# RL7005_IP_SVD register map
Vendor: Realtek
Registers are 32-bit, read-write, reset 0x0 unless marked. A register's access mark holds for its fields unless they carry their own. Offsets are from the block's base; [hi:lo] are bit positions; lines under a group give offsets from that group; {n}, {i} and the like mark numbered series.

## PAGE4
Base 0x40000000
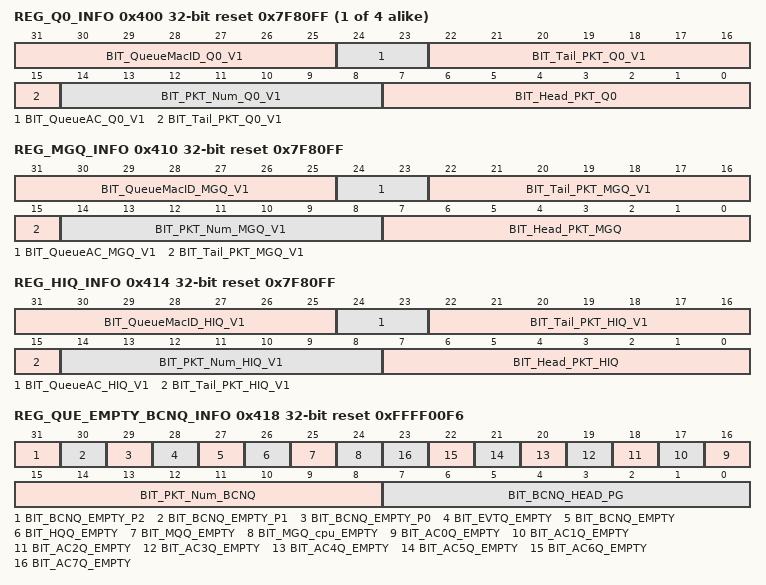
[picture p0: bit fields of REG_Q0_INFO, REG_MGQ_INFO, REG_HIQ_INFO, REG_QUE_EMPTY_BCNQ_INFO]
{0x400+4i} REG_Q{i}_INFO ro reset 0x7F80FF (i=0..3)
  [31:25] BIT_QueueMacID_Q{i}_V1 — MacID of head pkt
  [24:23] BIT_QueueAC_Q{i}_V1 — AC type of Queue {i}.
  [22:15] BIT_Tail_PKT_Q{i}_V1 — The head page of the last packet of Queue {i}.
  [14:8] BIT_PKT_Num_Q{i}_V1 — The total Queue {i} pkt number in TxPktbuffer
  [7:0] BIT_Head_PKT_Q{i} — The head page of the first packet of Queue {i}.
0x410 REG_MGQ_INFO ro reset 0x7F80FF
  [31:25] BIT_QueueMacID_MGQ_V1 — MacID of head pkt
  [24:23] BIT_QueueAC_MGQ_V1 — AC type of management Queue.
  [22:15] BIT_Tail_PKT_MGQ_V1 — The head page of the last packet of MGQ.
  [14:8] BIT_PKT_Num_MGQ_V1 — The total MGQ pkt number in TxPktbuffer
  [7:0] BIT_Head_PKT_MGQ — The head page of the first packet of MGQ.
0x414 REG_HIQ_INFO ro reset 0x7F80FF
  [31:25] BIT_QueueMacID_HIQ_V1 — MacID of head pkt
  [24:23] BIT_QueueAC_HIQ_V1 — AC type of High Queue.
  [22:15] BIT_Tail_PKT_HIQ_V1 — The head page of the last packet of HIQ.
  [14:8] BIT_PKT_Num_HIQ_V1 — The total HIQ pkt number in TxPktbuffer
  [7:0] BIT_Head_PKT_HIQ — The head page of the first packet of HIQ.
0x418 REG_QUE_EMPTY_BCNQ_INFO ro reset 0xFFFF00F6
  [31] BIT_BCNQ_EMPTY_P2 — When this bit is raised, beacon queue of PORT2 is empty. Report by MAC.
  [30] BIT_BCNQ_EMPTY_P1 — When this bit is raised, beacon queue of PORT1 is empty. Report by MAC.
  [29] BIT_BCNQ_EMPTY_P0 — When this bit is raised, beacon queue of PORT0 is empty. Report by MAC.
  [28] BIT_EVTQ_EMPTY — When this bit is raised, event queue is empty. Report by MAC.
  [27] BIT_BCNQ_EMPTY — When this bit is raised, beacon queue is empty. Report by MAC.
  [26] BIT_HQQ_EMPTY — When this bit is raised, High queue is empty. Report by MAC.
  [25] BIT_MQQ_EMPTY — When this bit is raised, MGQ queue is empty. Report by MAC.
  [24] BIT_MGQ_cpu_EMPTY — When this bit is raised, MGQ queue poll by cpu is empty. Report by MAC.
  [n+16] BIT_AC{n}Q_EMPTY (n=0..7) — When this bit is raised, AC{n} queue is empty. Report by MAC.
  [15:8] BIT_PKT_Num_BCNQ — The total BcnQ pkt number in TxPktbuffer
  [7:0] BIT_BCNQ_HEAD_PG — The head page of the first packet of Bcnq
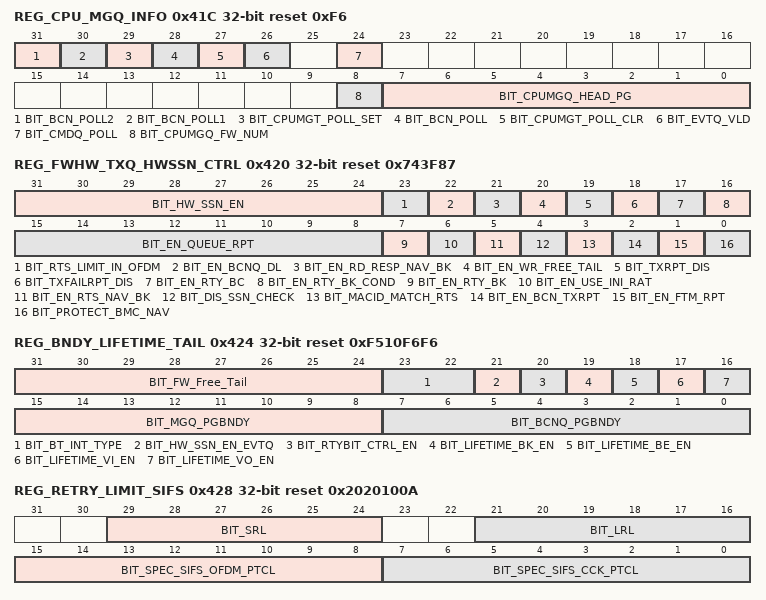
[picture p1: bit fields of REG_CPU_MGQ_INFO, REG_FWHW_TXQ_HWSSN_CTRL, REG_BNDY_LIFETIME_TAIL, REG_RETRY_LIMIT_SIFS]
0x41C REG_CPU_MGQ_INFO access per field reset 0xF6
  [31] BIT_BCN_POLL2 wo — Polling BCN Queue2 Packet. Not used in 8723F
  [30] BIT_BCN_POLL1 wo — Polling BCN Queue1 Packet
  [29] BIT_CPUMGT_POLL_SET wo — Polling to set CPU MGT Queue packet
  [28] BIT_BCN_POLL wo — Polling BCN Queue Packet
  [27] BIT_CPUMGT_POLL_CLR wo — Polling to clear CPU MGT Queue packet
  [26] BIT_EVTQ_VLD rw — SW set to 1, HW clear to 0 when evtq timeout or tx_finish
  [24] BIT_CMDQ_POLL wo — polling CMD packet
  [8] BIT_CPUMGQ_FW_NUM ro — The total cpu mgq fw number in TxPktbuffer
  [7:0] BIT_CPUMGQ_HEAD_PG ro — The head page of CPU MGQ
0x420 REG_FWHW_TXQ_HWSSN_CTRL reset 0x743F87
  [31:24] BIT_HW_SSN_EN — HW update the SSN [7:0], When this bit enable and EN_HWSEQ of TXDESC, MAC will overwrite MACHDR SEQ according to TXDESC QSEL [0] BIT_HWSEQ_VO_EN [1] BIT_HWSEQ_VI_EN [2] BIT_HWSEQ_BE_EN [3] BIT_HWSEQ_BK_EN [4] BIT_HWSEQ_MGT_EN [5] BIT_HWSEQ_HI_EN [6] BIT_HWSEQ_BCN_EN,don't care EN_HWSEQ of TXDESC [7] BIT_HWSEQ_CPUM_EN
  [23] BIT_RTS_LIMIT_IN_OFDM — Rts rate will not down to cck rate
  [22] BIT_EN_BCNQ_DL — 1: ptcl consider there is bcn pkt in TXBUF when bcn pkt first be transferd in; 0: mask bcn pkt num in bcn queue
  [21] BIT_EN_RD_RESP_NAV_BK — Control the RD responder NAV criteria for TX. When this bit is clear, RD responder may aggregates only according to the number of MPDUs existing in the TXPKTBUF, the limit of aggregation size and number, and also the break time. When this bit is set, RD responder will be under the RX NAV criteria for RD response sequence. No excess NAV is allowed
  [20] BIT_EN_WR_FREE_TAIL — 1: Drive write Bcnq_boundary, Hw will set free_tail in Boundary-1 0: no update
  [19] BIT_TXRPT_DIS — when this bit is enabled, HW will not generate txrpt for driver's fixed rate packets
  [18] BIT_TXFAILRPT_DIS — when this bit is enabled, HW will not generate txrpt for tx failed packets
  [17] BIT_EN_RTY_BC — When this bit is enabled, retry the broadcast packet
  [16] BIT_EN_RTY_BK_COND — AMPDU aggregation mode with retry MPDUs and new MPDUs. When this bit is enabled, if new MPDU's data rate is not the same as retry MPDUs' fallback data rate, the aggregation will be broken.
  [15:8] BIT_EN_QUEUE_RPT — 8723A/8812 1: HW will report tx_status 0: no report BIT0: BK Queue BIT1: BE Queue BIT2: VI Queue BIT3: VO Queue BIT4: MGT Queue BIT5: HI Queue BIT6: BCN Queue BIT7: CPU_MGT Queue
  [7] BIT_EN_RTY_BK — AMPDU aggregation mode with retry MPDUs and new MPDUs. When this bit is clear enabled, an AMPDU aggregates retried MPDU and new MPDU. All the aggregation criteria is still the same with normal AMPDU operation.
  [6] BIT_EN_USE_INI_RAT — 0: If Txdesc's USE RATE = 0 and this field is equal to 0, the datarate of TXRPT SRAM is used as tx pkt's datarate. (ECO flow) 1: TXInfo's datarate is used as tx pkt's datarate.
  [5] BIT_EN_RTS_NAV_BK — Control The RTS NAV criteria for TX. When this bit is clear, TX may aggregates only according to the number of MPDUs existing in the TXPKTBUF, the limit of aggregation size and number, and also the break time. When this bit is set, TX will be under the RTS NAV criteria. No excess RTS NAV is allowed.
  [4] BIT_DIS_SSN_CHECK — Disable checker the SSN rule when generating AMPDU TX cmd.
  [3] BIT_MACID_MATCH_RTS — Enable the packet that follow the RTS have same MACID
  [2] BIT_EN_BCN_TXRPT — 1: HW will report bcn tx_status 0: no report
  [1] BIT_EN_FTM_RPT — When this bit asserted, HW will report FTM rpt
  [0] BIT_PROTECT_BMC_NAV — Enable the NAV protection when transmit broadcast/multicast
0x424 REG_BNDY_LIFETIME_TAIL access per field reset 0xF510F6F6
  [31:24] BIT_FW_Free_Tail ro — Free Tail Page Number
  [23:22] BIT_BT_INT_TYPE rw — BT Interrupt type 01: PTA 10: CPU
  [21] BIT_HW_SSN_EN_EVTQ rw — HW update the SSN [8] for eventq
  [20] BIT_RTYBIT_CTRL_EN rw — 1: Enable Retry Count 0: Disable
  [19] BIT_LIFETIME_BK_EN rw — Enable BK queue lifetime function
  [18] BIT_LIFETIME_BE_EN rw — Enable BE queue lifetime function
  [17] BIT_LIFETIME_VI_EN rw — Enable VI queue lifetime function
  [16] BIT_LIFETIME_VO_EN rw — Enable VO queue lifetime function
  [15:8] BIT_MGQ_PGBNDY rw — TXDMA will pull CPU MGQ Pkt in this address.
  [7:0] BIT_BCNQ_PGBNDY rw — TXDMA will pull BCNQ Pkt in this address.
0x428 REG_RETRY_LIMIT_SIFS reset 0x2020100A
  [29:24] BIT_SRL — Short Retry Limit
  [21:16] BIT_LRL — Long Retry Limit
  [15:8] BIT_SPEC_SIFS_OFDM_PTCL — The spec SIFS value for duration calculation
  [7:0] BIT_SPEC_SIFS_CCK_PTCL — The spec SIFS value for duration calculation
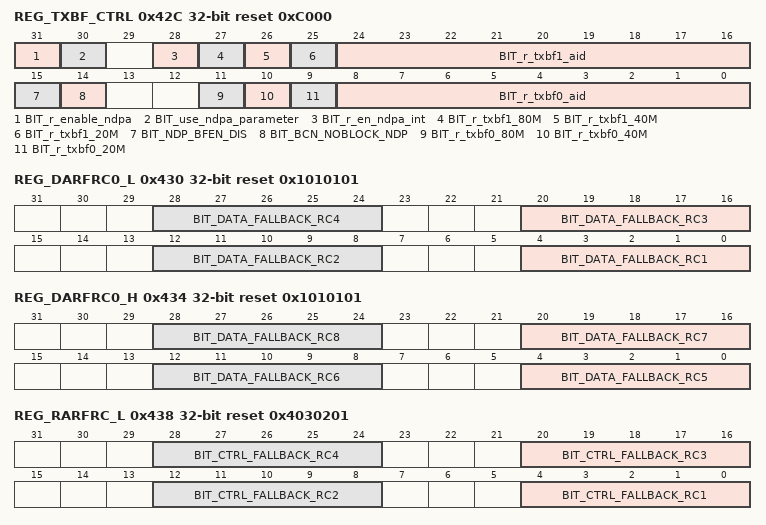
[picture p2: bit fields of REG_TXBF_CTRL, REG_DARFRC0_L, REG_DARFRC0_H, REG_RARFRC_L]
0x42C REG_TXBF_CTRL reset 0xC000
  [31] BIT_r_enable_ndpa — Set '1' for MAC to enable sending NDPA or NDP Announcement MPDU
  [30] BIT_use_ndpa_parameter — 1: NDPA rate and BW use reg0x45f settings 0: NDPA rate and BW use NDP settings in Tx descriptor
  [28] BIT_r_en_ndpa_int — 1: enable ndpa interrupt; 0: disable ndpa interrupt
  [27] BIT_r_txbf1_80M — TxBF status of beamformee1 @BW=80M.
  [26] BIT_r_txbf1_40M — TxBF status of beamformee1 @BW=40M
  [25] BIT_r_txbf1_20M — TxBF status of beamformee1 @BW=20M
  [24:16] BIT_r_txbf1_aid — P_AID[8:0] of the associated beamformee1
  [15] BIT_NDP_BFEN_DIS — 1: disable beamforming with NDP
  [14] BIT_BCN_NOBLOCK_NDP — beacon packet will not block NDP packet
  [11] BIT_r_txbf0_80M — TxBF status of beamformee0 @BW=80M
  [10] BIT_r_txbf0_40M — TxBF status of beamformee0 @BW=40M
  [9] BIT_r_txbf0_20M — TxBF status of beamformee0 @BW=20M
  [8:0] BIT_r_txbf0_aid — P_AID[8:0] of the associated beamformee0
0x430 REG_DARFRC0_L reset 0x1010101
  [8n-4:8n-8] BIT_DATA_FALLBACK_RC{n} (n=1..4) — Data Auto Rate Fallback Retry Count After the number of retry, HW will fall back the rate to the next enabled MAC in ARFR.
0x434 REG_DARFRC0_H reset 0x1010101
  [8n-36:8n-40] BIT_DATA_FALLBACK_RC{n} (n=5..8) — Data Auto Rate Fallback Retry Count After the number of retry, HW will fall back the rate to the next enabled MAC in ARFR.
0x438 REG_RARFRC_L reset 0x4030201
  [8n-4:8n-8] BIT_CTRL_FALLBACK_RC{n} (n=1..4) — RTS Auto Rate Fallback Retry Count After the number of retry, HW will fall back the rate to the next enabled MAC in ARFR.
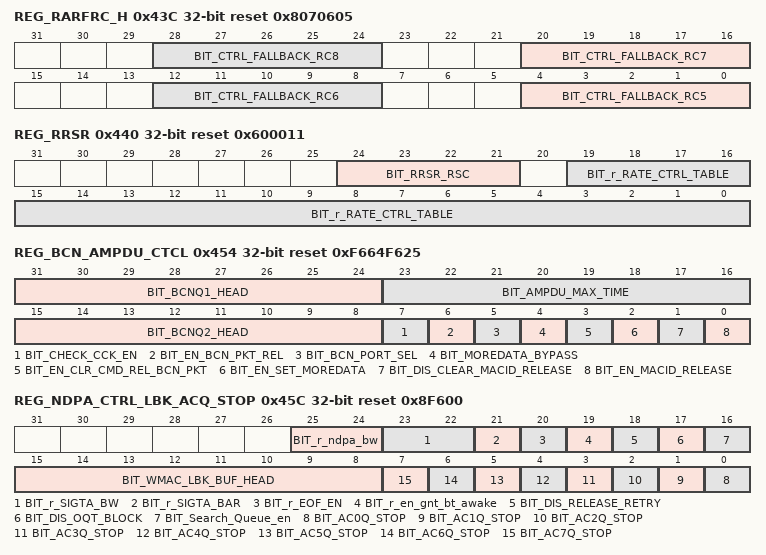
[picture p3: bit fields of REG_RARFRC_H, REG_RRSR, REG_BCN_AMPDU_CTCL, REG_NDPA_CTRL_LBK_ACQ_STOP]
0x43C REG_RARFRC_H reset 0x8070605
  [8n-36:8n-40] BIT_CTRL_FALLBACK_RC{n} (n=5..8) — RTS Auto Rate Fallback Retry Count After the number of retry, HW will fall back the rate to the next enabled MAC in ARFR.
0x440 REG_RRSR reset 0x600011
  [24:21] BIT_RRSR_RSC — Response frame sub-channel configuration. Response frames (CTS, ACK, BA) are transmitted in the following condition. 00: Primary 20Mhz BW(0x483[3:0] = 0x8AC[5:2]). 01: Follow Rx packet BW mode. 10: Duplicate mode.
  [19:0] BIT_r_RATE_CTRL_TABLE — Data Rate Control Table Register BitMap to indicate the response/protection/expected_response rate to use in this BSS. All management and control response frames should obey the rates set in the bitmap. Each bit is mapped as the following: Bit[0:3] = {1M, 2M, 5.5M, 11M } Bit[4:11] = {6M, 9M, 12M, 18M, 24M, 36M, 48M, 54M} Bit[12:19] = HT MCS0~MCS7 Response rate must be less than or equal to the rate of the initiating frame. If none of the bits are set, no response is generated by Rtl8712. If both the legacy rates and HT rates are defined as Basic Rates, fill in only the legacy portion of the bitmap. If only HT rates are defined as Basic Rates, fill in both the legacy and HT portion of the bitmap.
0x454 REG_BCN_AMPDU_CTCL reset 0xF664F625
  [31:24] BIT_BCNQ1_HEAD — TXDMA will pull BCNQ1 Pkt in this address. Port1 & VAP 1/3/5/7 of port0
  [23:16] BIT_AMPDU_MAX_TIME — AMPDU duration limit in the unit of 32us.
  [15:8] BIT_BCNQ2_HEAD — TXDMA will pull BCNQ2 Pkt in this address. Port2, NAN
  [7] BIT_CHECK_CCK_EN — If this bit is set, HW check Tx pkt's data rate. When data rate is CCK rate, modify the rate to NON_CCK_RATE.
  [6] BIT_EN_BCN_PKT_REL — If this bit is set, the BCN pkt will be set to non-valid after BCN TX.
  [5] BIT_BCN_PORT_SEL — This bit use to select BCN on port 1 or port 0. This just useful in USB/SDIO interface.
  [4] BIT_MOREDATA_BYPASS — If this bit is set, the moredata bit will controlled by DES, otherwise controlled by PTCL according TXPKTBUF status.
  [3] BIT_EN_CLR_CMD_REL_BCN_PKT — If this bit is set, the BCN pkt will be set to non-valid when scheduler clear TX BCN CMD even non-TX.
  [2] BIT_EN_SET_MOREDATA — 1: Enable HW set the more data bit of the PKT that MACID release function tx. 0: Disable HW set the more data bit of the PKT that MACID release function tx.
  [1] BIT_DIS_CLEAR_MACID_RELEASE — 1: HW No clear MACID Release bit after release the pkt. 0: HW will clear MACID Release bit after release the pkt.
  [0] BIT_EN_MACID_RELEASE — 1: Enable MACID Release function. (same as MACID DROP) 0: Disable MACID Release function.
0x458 REG_AMPDU_MAX_LENGTH reset 0xFFFFFFFF
  [31:0] BIT_AMPDU_MAX_LENGTH — AMPDU length limit
0x45C REG_NDPA_CTRL_LBK_ACQ_STOP access per field reset 0x8F600
  [25:24] BIT_r_ndpa_bw rw — NDPA bandwidth setting 3: 160M 2: 80M 1: 40M 0: 20M
  [23:22] BIT_r_SIGTA_BW rw — Enable signaling TA in duplicate BW, valid if EN_SIGTA = 1 in TX DESC
  [21] BIT_r_SIGTA_BAR rw — Enable BAR signaling TA in duplicate BW
  [20] BIT_r_EOF_EN rw — when set to 1, enable eof packet qos packet,but also need set agg_en to 0 in tx_desc
  [19] BIT_r_en_gnt_bt_awake rw — Enable pollute bit function.(C card ECO item, modify hardware circuit and add two options) 0: Disable 1: Enable When (GNT_BT option/LTE_RX option/(GNT_WL==0)) == 1, retry count can't increase if Tx fail. One or more packets will record in polluted bit field of txreport when txreport generates in Tx ok or tx drop.
  [18] BIT_DIS_RELEASE_RETRY rw — when release one packet for a macid, retry should happen on the same ACQ. Set 1 to remove this requirement
  [17] BIT_DIS_OQT_BLOCK rw — If this bit is set, the OQT will not block by all AC queues occupied by other MACID.
  [16] BIT_Search_Queue_en rw — Search queue request enable in ptcl idle:0 disable; 1 enable
  [15:8] BIT_WMAC_LBK_BUF_HEAD rw — In delay MAC LBK mode, this register indicate the LBK BUF head page. When this buffer size is not enough for LBK packet length, LBK test may fail. In ARP/NS mode, this register indicate the ARP/NS response packet head page.
  [n] BIT_AC{n}Q_STOP ro (n=0..7) — When this bit is raised, AC{n} queue is stop. Report by MAC.
0x460 REG_RD_RESP_PKT_TH reset 0x3000000
  [29:24] BIT_RD_RESP_PKT_TH — When RD_CTRL responder enables, and the granted AC queue packet number is beyond this threshold, then responder will carry More PPDU =1 and piggyback data frames back.
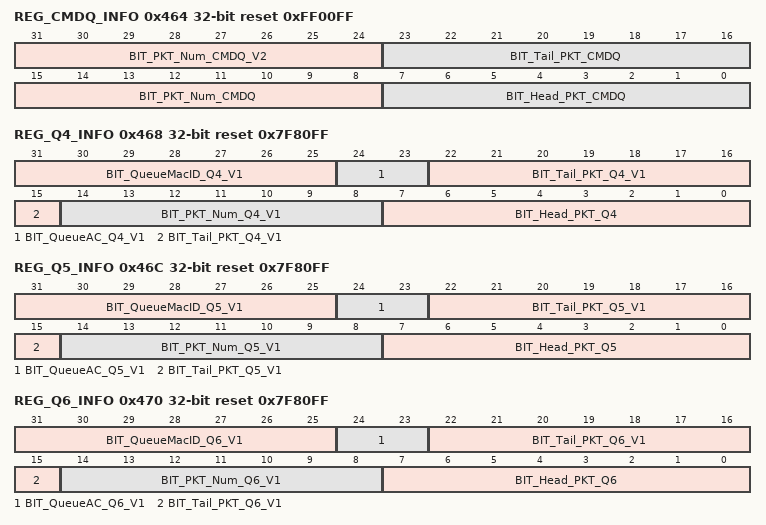
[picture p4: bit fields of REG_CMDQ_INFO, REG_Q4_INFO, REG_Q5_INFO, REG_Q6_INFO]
0x464 REG_CMDQ_INFO ro reset 0xFF00FF
  [31:24] BIT_PKT_Num_CMDQ_V2 — The total CMD Queue pkt number in TxPktbuffer
  [23:16] BIT_Tail_PKT_CMDQ — The head page of the last packet of Queue 4.
  [15:8] BIT_PKT_Num_CMDQ — The total Queue 4 pkt number in TxPktbuffer
  [7:0] BIT_Head_PKT_CMDQ — The head page of the first packet of Queue 4.
0x468 REG_Q4_INFO ro reset 0x7F80FF
  [31:25] BIT_QueueMacID_Q4_V1 — MacID of head pkt
  [24:23] BIT_QueueAC_Q4_V1 — AC type of Queue 4.
  [22:15] BIT_Tail_PKT_Q4_V1 — The head page of the last packet of Queue 4.
  [14:8] BIT_PKT_Num_Q4_V1 — The total Queue 4 pkt number in TxPktbuffer
  [7:0] BIT_Head_PKT_Q4 — The head page of the first packet of Queue 4.
0x46C REG_Q5_INFO ro reset 0x7F80FF
  [31:25] BIT_QueueMacID_Q5_V1 — MacID of head pkt
  [24:23] BIT_QueueAC_Q5_V1 — AC type of Queue 5.
  [22:15] BIT_Tail_PKT_Q5_V1 — The head page of the last packet of Queue 5.
  [14:8] BIT_PKT_Num_Q5_V1 — The total Queue 5 pkt number in TxPktbuffer
  [7:0] BIT_Head_PKT_Q5 — The head page of the first packet of Queue5.
0x470 REG_Q6_INFO ro reset 0x7F80FF
  [31:25] BIT_QueueMacID_Q6_V1 — MacID of head pkt
  [24:23] BIT_QueueAC_Q6_V1 — AC type of Queue 6.
  [22:15] BIT_Tail_PKT_Q6_V1 — The head page of the last packet of Queue 6.
  [14:8] BIT_PKT_Num_Q6_V1 — The total Queue 6 pkt number in TxPktbuffer
  [7:0] BIT_Head_PKT_Q6 — The head page of the first packet of Queue 6.
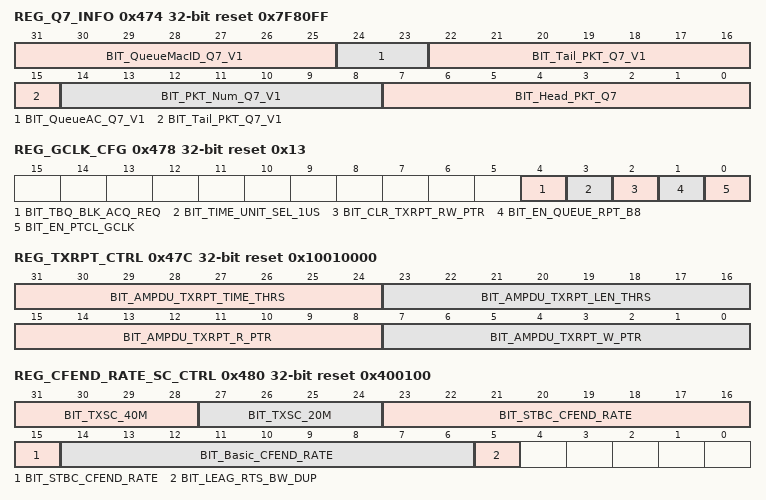
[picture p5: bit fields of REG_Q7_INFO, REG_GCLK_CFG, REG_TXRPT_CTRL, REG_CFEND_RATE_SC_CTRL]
0x474 REG_Q7_INFO ro reset 0x7F80FF
  [31:25] BIT_QueueMacID_Q7_V1 — MacID of head pkt
  [24:23] BIT_QueueAC_Q7_V1 — AC type of Queue 7.
  [22:15] BIT_Tail_PKT_Q7_V1 — The head page of the last packet of Queue 7.
  [14:8] BIT_PKT_Num_Q7_V1 — The total Queue 7 pkt number in TxPktbuffer
  [7:0] BIT_Head_PKT_Q7 — The head page of the first packet of Queue 7.
0x478 REG_GCLK_CFG reset 0x13
  [4] BIT_TBQ_BLK_ACQ_REQ — 1: start select acq to gen_cmd need to wait tbq_txreq == 1
  [3] BIT_TIME_UNIT_SEL_1US — select queue_time and lifetime unit 1: unit 1us 0: unit 256us
  [2] BIT_CLR_TXRPT_RW_PTR — Write 1 to clear BIT_AMPDU_TXRPT_W_PTR & BIT_AMPDU_TXRPT_R_PTR (0x47C / 0x47D)
  [1] BIT_EN_QUEUE_RPT_B8 — [8] of BIT_EN_QUEUE_RPT, BIT8: EVENT Queue
  [0] BIT_EN_PTCL_GCLK — 1: enable clock gating
0x47C REG_TXRPT_CTRL access per field reset 0x10010000
  [31:24] BIT_AMPDU_TXRPT_TIME_THRS rw — Time threshold of ampdu txrpt
  [23:16] BIT_AMPDU_TXRPT_LEN_THRS rw — Length threshold of ampdu txrpt
  [15:8] BIT_AMPDU_TXRPT_R_PTR rw — Read pointer of ampdu txrpt
  [7:0] BIT_AMPDU_TXRPT_W_PTR ro — Write pointer of ampdu txrpt
0x480 REG_CFEND_RATE_SC_CTRL reset 0x400100
  [31:28] BIT_TXSC_40M — Value of Data frame Tx sub-carrier mode 40MHz
  [27:24] BIT_TXSC_20M — Value of Data frame Tx sub-carrier mode 20MHz
  [23:15] BIT_STBC_CFEND_RATE — The initial rate for STBC CFEND frame transmitted as EDCA originator. The response control frame shall be selected by the definition of 802.11n. MCS0
  [14:6] BIT_Basic_CFEND_RATE — The initial rate for basic CFEND frame transmitted as EDCA originator. The response control frame shall be selected by the definition of 802.11n. OFDM6M
  [5] BIT_LEAG_RTS_BW_DUP — If this bit is set, leag rate RTS use Duplicate in 40M BW / 80M BW.
0x484 REG_MACID_SLEEP3
  [31:0] BIT_MACID127_96_PKTSLEEP — Macid 127~Macid 96 Packet Sleep (per bit controlled)
0x488 REG_MACID_SLEEP1
  [31:0] BIT_MACID63_32_PKTSLEEP — Macid 63~Macid 32 Packet Sleep (per bit controlled)
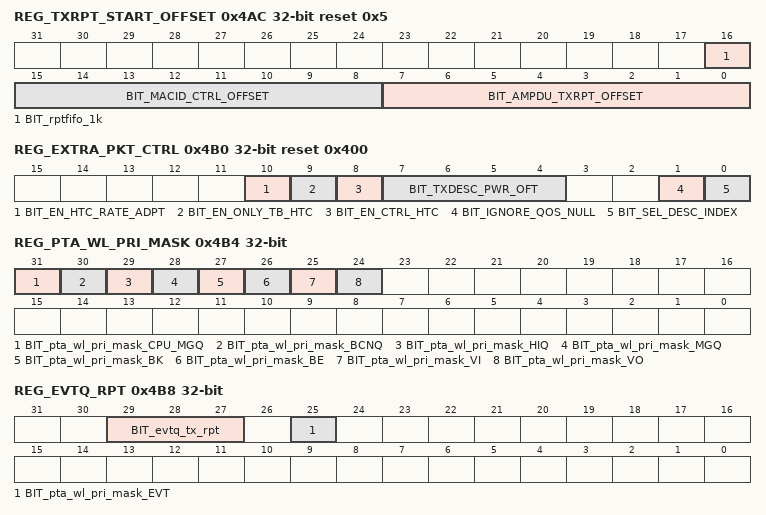
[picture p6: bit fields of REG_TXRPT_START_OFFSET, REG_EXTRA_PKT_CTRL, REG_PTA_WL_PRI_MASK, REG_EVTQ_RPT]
0x4AC REG_TXRPT_START_OFFSET reset 0x5
  [16] BIT_rptfifo_1k — select the size of rptfifo
  [15:8] BIT_MACID_CTRL_OFFSET — offset of macid control: ctrl_info in the start of txrptbuf
  [7:0] BIT_AMPDU_TXRPT_OFFSET — offset of AMPDU txrpt
0x4B0 REG_EXTRA_PKT_CTRL reset 0x400
  [10] BIT_EN_HTC_RATE_ADPT — 1: if tx data rate fallback to CCK/OFDM rate, HW will remove HTC field in mac header
  [9] BIT_EN_ONLY_TB_HTC — 1: only TB can carry HTC field
  [8] BIT_EN_CTRL_HTC — 1: rts/cts2s/cts2ap/bar will carry HTC field by ctrl_wrapper frame, valid when txdesc.HTC = 1 0: rts/cts2s/cts2ap/bar will NOT carry HTC field even though txdesc.HTC = 1
  [7:4] BIT_TXDESC_PWR_OFT — indicate the tx power compensation of TXDESC.TX_PWR_OFT, unit: 1dbm
  [1] BIT_IGNORE_QOS_NULL — 1: will not TX QoS Null when rx Basic trigger
  [0] BIT_SEL_DESC_INDEX — 1: select rate index from txdesc
0x4B4 REG_PTA_WL_PRI_MASK
  [31] BIT_pta_wl_pri_mask_CPU_MGQ — PTCL send wl_pri to PTA when pktbuf has CPU_MGQ packet
  [30] BIT_pta_wl_pri_mask_BCNQ — PTCL send wl_pri to PTA when pktbuf has BCNQ packet
  [29] BIT_pta_wl_pri_mask_HIQ — PTCL send wl_pri to PTA when pktbuf has HIQ packet
  [28] BIT_pta_wl_pri_mask_MGQ — PTCL send wl_pri to PTA when pktbuf has MGQ packet
  [27] BIT_pta_wl_pri_mask_BK — PTCL send wl_pri to PTA when pktbuf has BKQ packet
  [26] BIT_pta_wl_pri_mask_BE — PTCL send wl_pri to PTA when pktbuf has BEQ packet
  [25] BIT_pta_wl_pri_mask_VI — PTCL send wl_pri to PTA when pktbuf has VIQ packet
  [24] BIT_pta_wl_pri_mask_VO — PTCL send wl_pri to PTA when pktbuf has VOQ packet
0x4B8 REG_EVTQ_RPT access per field
  [29:27] BIT_evtq_tx_rpt ro — *000: nothing *100: pktok *010: pktfail / timeout *001: evtq_tx_area_75
  [25] BIT_pta_wl_pri_mask_EVT rw — PTCL send wl_pri to PTA when pktbuf has EVTQ packet
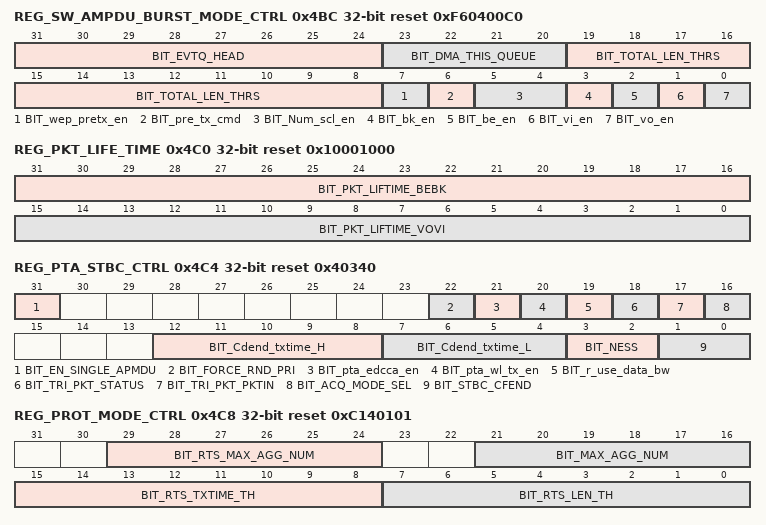
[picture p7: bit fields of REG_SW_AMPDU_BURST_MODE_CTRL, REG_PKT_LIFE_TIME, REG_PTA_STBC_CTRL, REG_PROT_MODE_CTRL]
0x4BC REG_SW_AMPDU_BURST_MODE_CTRL reset 0xF60400C0
  [31:24] BIT_EVTQ_HEAD — TXDMA will pull eventq Pkt in this address. NAN
  [23:20] BIT_DMA_THIS_QUEUE — scheduler enable
  [19:8] BIT_TOTAL_LEN_THRS — aggregation length over threshold then fetch pad packet in early mode
  [7] BIT_wep_pretx_en — Enable pretx for WEP/TKIP, to allow a slower security clock
  [6] BIT_pre_tx_cmd — enable pre tx cmd to use aggr more packet
  [5:4] BIT_Num_scl_en — SW MPDU Burst mode select 00: each length field for 1 MPDU 01: each length field is the summation of 2 MPDUs 10: each length field is the summation of 3 MPDUs 11: each length field is the summation of 4 MPDUs Note: the total MPDU number is no more than 15.
  [3] BIT_bk_en — AMPDU burst mode enable for AC_BK queue
  [2] BIT_be_en — AMPDU burst mode enable for AC_BE queue
  [1] BIT_vi_en — AMPDU burst mode enable for AC_VI queue
  [0] BIT_vo_en — AMPDU burst mode enable for AC_VO queue
0x4C0 REG_PKT_LIFE_TIME reset 0x10001000
  [31:16] BIT_PKT_LIFTIME_BEBK — BE/BK packet lifetime unit: 256us
  [15:0] BIT_PKT_LIFTIME_VOVI — VO/VI packet lifetime unit: 256us
0x4C4 REG_PTA_STBC_CTRL reset 0x40340
  [31] BIT_EN_SINGLE_APMDU — If this bit is set, Enable single sub-frame APMDU.
  [22] BIT_FORCE_RND_PRI — queue select priority control 1:old round robin method 0:depend on last selected queue
  [21] BIT_pta_edcca_en — 0 : wl_tx signal to PTA does not consider EDCCA 1 : wl_tx signal to PTA consider EDCCA
  [20] BIT_pta_wl_tx_en — enable WL PTA (should be set in init MAC)
  [19] BIT_r_use_data_bw — 1 : Use des2_data_bw for this packet 0 : when des1_cca_rts = 2'b10, update_bw depend on ch_bw_status
  [18] BIT_TRI_PKT_STATUS
  [17] BIT_TRI_PKT_PKTIN — If trigger frame is transmitted into txpktbuf, HW generates interrupt 1: Enable 0: Disable
  [16] BIT_ACQ_MODE_SEL — 1: Enable 88C 4AC Mode 0: Enable 8723 ACQ0~7 Mode
  [12:8] BIT_Cdend_txtime_H — Cfend packet txtime bit[8:4]
  [7:4] BIT_Cdend_txtime_L — Cfend packet txtime bit[3:0]
  [3:2] BIT_NESS — NESS
  [1:0] BIT_STBC_CFEND — CFEND STBC
0x4C8 REG_PROT_MODE_CTRL reset 0xC140101
  [29:24] BIT_RTS_MAX_AGG_NUM — In RTS frame exchange sequence, the maximum aggregation packet number limit is defined by this register, unit is byte
  [21:16] BIT_MAX_AGG_NUM — the maximum aggregation packet number limit,unit is byte
  [15:8] BIT_RTS_TXTIME_TH — RTS packet txtime threshold, unit is 64 us
  [7:0] BIT_RTS_LEN_TH — RTS packet Length threshold, unit is 128 bytes
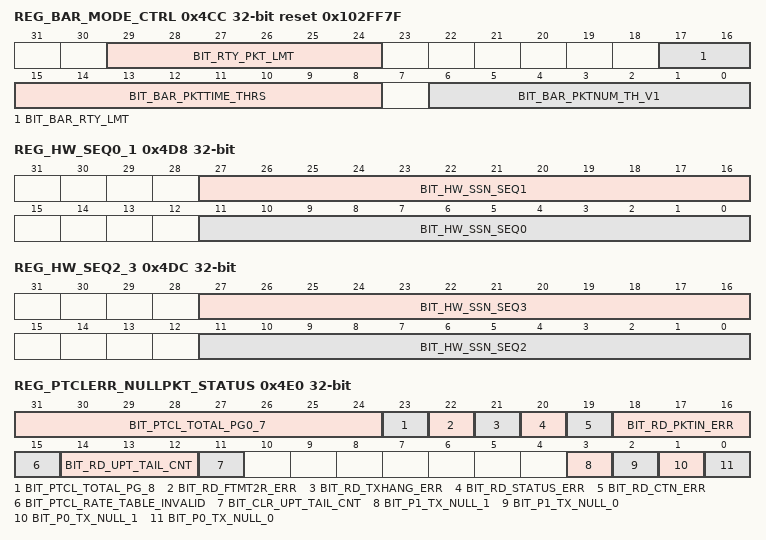
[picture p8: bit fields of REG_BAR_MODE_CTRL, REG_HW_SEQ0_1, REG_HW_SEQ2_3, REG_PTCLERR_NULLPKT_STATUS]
0x4CC REG_BAR_MODE_CTRL reset 0x102FF7F
  [29:24] BIT_RTY_PKT_LMT — retry packet limit
  [17:16] BIT_BAR_RTY_LMT — BAR retry limit
  [15:8] BIT_BAR_PKTTIME_THRS — BAR packet time thrs
  [6:0] BIT_BAR_PKTNUM_TH_V1 — BAR Pktnum Thrs
0x4D0 REG_MACID_SLEEP2
  [31:0] BIT_MACID95_64PKTSLEEP — Macid 95~Macid 64 Packet Sleep (per bit controlled)
0x4D4 REG_MACID_SLEEP
  [31:0] BIT_MACID31_0_PKTSLEEP — Macid31 ~ Macid 0Packet Sleep. (per bit controlled)
0x4D8 REG_HW_SEQ0_1
  [27:16] BIT_HW_SSN_SEQ1 — When TXDESC HWSEQEN is set, MAC will overwrite SEQ control by this register. Before DRV hand over the SEQ control to HW, DRV may set the current SEQ to this register. When DRV will take back the SEQ control from HW, DRV may get the current sequence from this register.
  [11:0] BIT_HW_SSN_SEQ0 — When TXDESC HWSEQEN is set, MAC will overwrite SEQ control by this register. Before DRV hand over the SEQ control to HW, DRV may set the current SEQ to this register. When DRV will take back the SEQ control from HW, DRV may get the current sequence from this register.
0x4DC REG_HW_SEQ2_3
  [27:16] BIT_HW_SSN_SEQ3 — When TXDESC HWSEQEN is set, MAC will overwrite SEQ control by this register. Before DRV hand over the SEQ control to HW, DRV may set the current SEQ to this register. When DRV will take back the SEQ control from HW, DRV may get the current sequence from this register.
  [11:0] BIT_HW_SSN_SEQ2 — When TXDESC HWSEQEN is set, MAC will overwrite SEQ control by this register. Before DRV hand over the SEQ control to HW, DRV may set the current SEQ to this register. When DRV will take back the SEQ control from HW, DRV may get the current sequence from this register.
0x4E0 REG_PTCLERR_NULLPKT_STATUS ro
  [31:24] BIT_PTCL_TOTAL_PG0_7 — Total Page in PTCL
  [23] BIT_PTCL_TOTAL_PG_8 — Total Page in PTCL
  [22] BIT_RD_FTMT2R_ERR — Indicates the timeout error in FTM t2r report
  [21] BIT_RD_TXHANG_ERR — Indicates the txhang error in RDG mode
  [20] BIT_RD_STATUS_ERR — Indicates the status error in RDG mode
  [19] BIT_RD_CTN_ERR — Indicates the cnt error in RDG mode
  [18:16] BIT_RD_PKTIN_ERR — Indicates the pktin error in RDG mode
  [15] BIT_PTCL_RATE_TABLE_INVALID — during rate fallback process, if the all rate table is invalid, then assert ERROR FLAG
  [14:12] BIT_RD_UPT_TAIL_CNT — SW update free_tail page counter
  [11] BIT_CLR_UPT_TAIL_CNT — write 1 to clear BIT_RD_UPT_TAIL_CNT, pulse
  [3] BIT_P1_TX_NULL_1 — Port 1 Tx Null 1 packet ok indicator
  [2] BIT_P1_TX_NULL_0 — Port 1 Tx Null 0 packet ok indicator
  [1] BIT_P0_TX_NULL_1 — Port 0 Tx Null 1 packet ok indicator
  [0] BIT_P0_TX_NULL_0 — Port 0 Tx Null 0 packet ok indicator
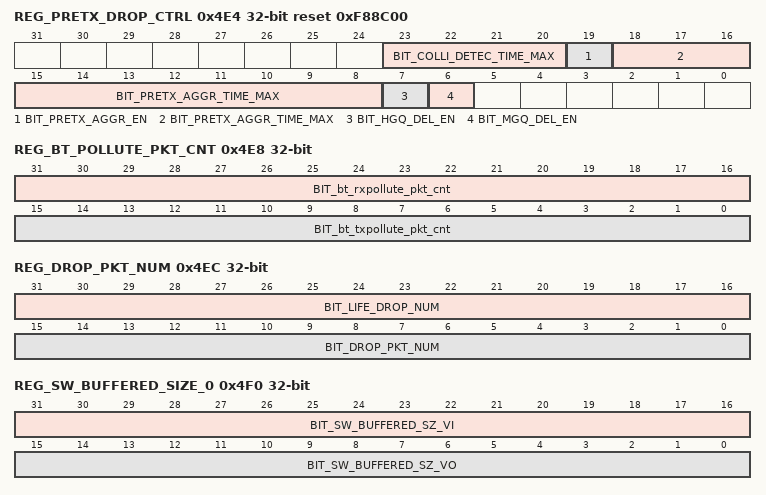
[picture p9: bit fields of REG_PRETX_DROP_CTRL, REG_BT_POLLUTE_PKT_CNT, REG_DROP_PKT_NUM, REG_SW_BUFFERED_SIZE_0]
0x4E4 REG_PRETX_DROP_CTRL reset 0xF88C00
  [23:20] BIT_COLLI_DETEC_TIME_MAX — 0~15: The field indicated collision detect time for broadcast or Beacon packet.(unit: us)
  [19] BIT_PRETX_AGGR_EN — 1: enable PRETX function, default is enable 0: disable PRETX function
  [18:8] BIT_PRETX_AGGR_TIME_MAX — If BIT_PRETX_AGGR_EN = 1, the bits will count down after PHYTXON signal asserting every transmission in pre-tx mode.(Default: 23F, mac_clk = 20MHz, 3us;Smart,mac_clk = 40MHz, 3.5us)
  [7] BIT_HGQ_DEL_EN — 1: HGQ packet will be dropped when enable macid delete function; 0: HGQ packet cannot be dropped
  [6] BIT_MGQ_DEL_EN — 1: MGQ packet will be dropped when enable macid delete function; 0: MGQ packet cannot be dropped
0x4E8 REG_BT_POLLUTE_PKT_CNT ro
  [31:16] BIT_bt_rxpollute_pkt_cnt — count the tx fail pkt caused by bt RX pollute, write 0x4E8[31] will clear the counter
  [15:0] BIT_bt_txpollute_pkt_cnt — count the tx fail pkt caused by bt TX pollute, write 0x4E8[15] will clear the counter
0x4EC REG_DROP_PKT_NUM
  [31:16] BIT_LIFE_DROP_NUM — TIE 0 in 8723F
  [15:0] BIT_DROP_PKT_NUM — Statistic the number of dropped packets
0x4F0 REG_SW_BUFFERED_SIZE_0
  [31:16] BIT_SW_BUFFERED_SZ_VI — SW update. Buffered packet size of VIQ, used to update BSR. Unit: byte
  [15:0] BIT_SW_BUFFERED_SZ_VO — SW update. Buffered packet size of VOQ, used to update BSR. Unit: byte
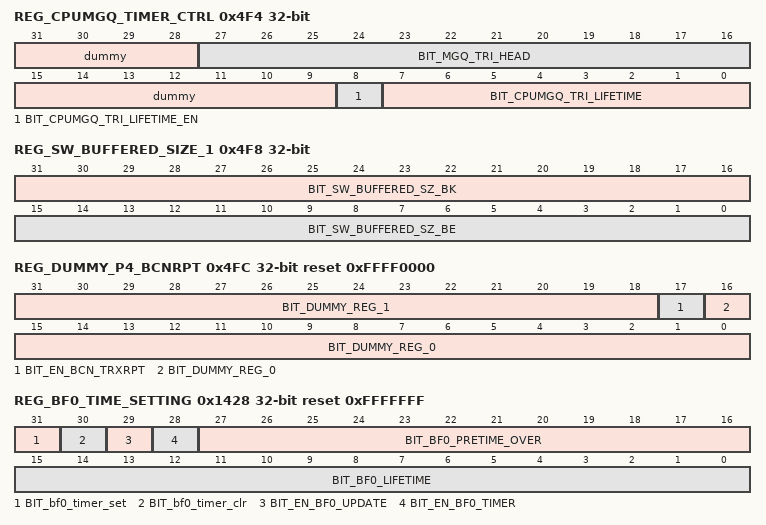
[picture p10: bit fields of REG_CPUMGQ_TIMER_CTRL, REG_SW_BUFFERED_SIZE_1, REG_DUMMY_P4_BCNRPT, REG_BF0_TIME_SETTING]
0x4F4 REG_CPUMGQ_TIMER_CTRL
  [31:28] dummy
  [27:16] BIT_MGQ_TRI_HEAD — The head page of the CPUMGQ pkt If the CPUMGQ is triggered by TX TIMER.
  [15:9] dummy
  [8] BIT_CPUMGQ_TRI_LIFETIME_EN — When this bit is set, enable the lifetime function. This lifetime threshold only affect CPUMGQ trigger from Tx_Timer.
  [7:0] BIT_CPUMGQ_TRI_LIFETIME — LIFETIME Threshold: Unit = 256us. When CPU MgntQ is triggered, If BIT_CPUMGQ_TRI_LIFETIME_EN = 1, count down. If BIT_CPUMGQ_TRI_LIFETIME_EN = 0, do nothing.
0x4F8 REG_SW_BUFFERED_SIZE_1
  [31:16] BIT_SW_BUFFERED_SZ_BK — SW update. Buffered packet size of BKQ, used to update BSR. Unit: byte
  [15:0] BIT_SW_BUFFERED_SZ_BE — SW update. Buffered packet size of BEQ, used to update BSR. Unit: byte
0x4FC REG_DUMMY_P4_BCNRPT reset 0xFFFF0000
  [31:18] BIT_DUMMY_REG_1 — dummy reg
  [17] BIT_EN_BCN_TRXRPT — If this bit is set, PTCL will write BCN TRXRPT when BCNOK/BCNERR INT. FW have clear this bit before enter LPS 32K mode.
  [16:0] BIT_DUMMY_REG_0 — dummy reg
0x1424 REG_AESIV_SETTING reset 0x3
  [11:0] BIT_AESIV_OFFSET — aesiv offset in txrpt buffer (Unit:128Bytes).
0x1428 REG_BF0_TIME_SETTING access per field reset 0xFFFFFFF
  [31] BIT_bf0_timer_set ro — write 1 to set beamforming 0 timer to BIT_bf0_lifetime
  [30] BIT_bf0_timer_clr ro — write 1 to clear beamforming 0 timer to 0
  [29] BIT_EN_BF0_UPDATE rw — 1: when tx ndp ok/fail, enable to update beamforming 0 timer
  [28] BIT_EN_BF0_TIMER rw — beamforming 0 timer enable
  [27:16] BIT_BF0_PRETIME_OVER rw — beamforming 0 pre timeout time
  [15:0] BIT_BF0_LIFETIME rw — beamforming 0 life time
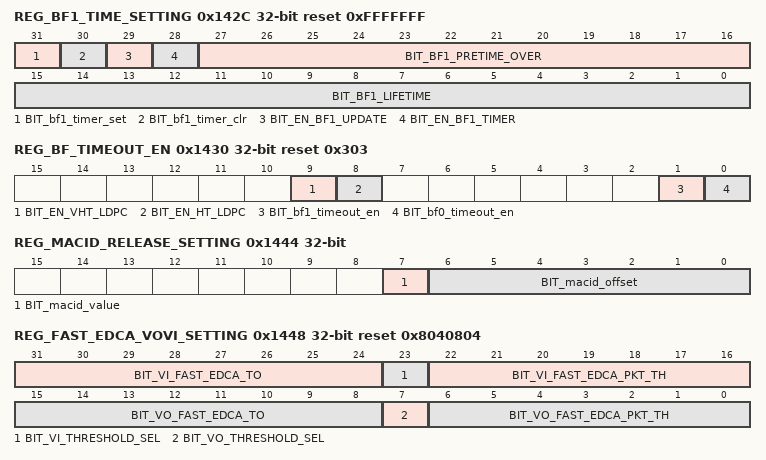
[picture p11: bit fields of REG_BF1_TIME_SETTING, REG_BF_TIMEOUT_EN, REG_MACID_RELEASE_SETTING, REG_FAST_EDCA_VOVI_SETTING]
0x142C REG_BF1_TIME_SETTING access per field reset 0xFFFFFFF
  [31] BIT_bf1_timer_set ro — write 1 to set beamforming 1 timer to BIT_bf1_lifetime
  [30] BIT_bf1_timer_clr ro — write 1 to clear beamforming 1 timer to 0
  [29] BIT_EN_BF1_UPDATE rw — 1: when tx ndp ok/fail, enable to update beamforming 1 timer
  [28] BIT_EN_BF1_TIMER rw — beamforming 1 timer enable
  [27:16] BIT_BF1_PRETIME_OVER rw — beamforming 1 pre timeout time
  [15:0] BIT_BF1_LIFETIME rw — beamforming 1 life time
0x1430 REG_BF_TIMEOUT_EN reset 0x303
  [9] BIT_EN_VHT_LDPC — 1: enable ldpc in vht rate mode
  [8] BIT_EN_HT_LDPC — 1: enable ldpc in ht rate mode
  [1] BIT_bf1_timeout_en — 1: when beamforming 1 timer count to 0,then disable beamforming 0
  [0] BIT_bf0_timeout_en — 1: when beamforming 0 timer count to 0,then disable beamforming 0
0x1434 REG_MACID_RELEASE0
  [31:0] BIT_MACID31_0_RELEASE — Macid31~Macid0 Release(per bit controlled)
0x1438 REG_MACID_RELEASE1
  [31:0] BIT_MACID63_32_RELEASE — Macid63~Macid32 Release(per bit controlled)
0x143C REG_MACID_RELEASE2
  [31:0] BIT_MACID95_64_RELEASE — Macid95~Macid64 Release (per bit controlled)
0x1440 REG_MACID_RELEASE3
  [31:0] BIT_MACID127_96_RELEASE — Macid127~Macid96 Release (per bit controlled)
0x1444 REG_MACID_RELEASE_SETTING
  [7] BIT_macid_value — write this field to set REG_macid_release[BIT_macid_offset] = BIT_macid_value
  [6:0] BIT_macid_offset — write this field to set REG_macid_release[BIT_macid_offset] = BIT_macid_value
0x1448 REG_FAST_EDCA_VOVI_SETTING reset 0x8040804
  [31:24] BIT_VI_FAST_EDCA_TO — vi queue fast edca timeout value
  [23] BIT_VI_THRESHOLD_SEL — 1: use all vi queue pktnum compare to pktnum_threshold; 0: use single macid pktnum compare to pktnum_threshold;
  [22:16] BIT_VI_FAST_EDCA_PKT_TH — vi queue fast edca pkt number threshold
  [15:8] BIT_VO_FAST_EDCA_TO — vo queue fast edca timeout value
  [7] BIT_VO_THRESHOLD_SEL — 1: use all vo queue pktnum compare to pktnum_threshold; 0: use single macid pktnum compare to pktnum_threshold;
  [6:0] BIT_VO_FAST_EDCA_PKT_TH — vo queue fast edca pkt number threshold
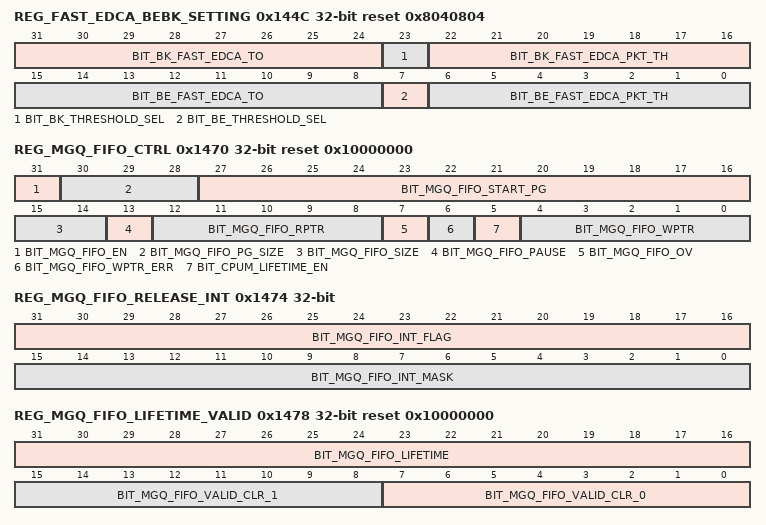
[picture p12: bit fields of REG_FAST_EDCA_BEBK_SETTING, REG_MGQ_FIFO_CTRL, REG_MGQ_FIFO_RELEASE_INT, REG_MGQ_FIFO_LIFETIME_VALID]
0x144C REG_FAST_EDCA_BEBK_SETTING reset 0x8040804
  [31:24] BIT_BK_FAST_EDCA_TO — bk queue fast edca timeout value
  [23] BIT_BK_THRESHOLD_SEL — 1: use all bk queue pktnum compare to pktnum_threshold; 0: use single macid pktnum compare to pktnum_threshold;
  [22:16] BIT_BK_FAST_EDCA_PKT_TH — bk queue fast edca pkt number threshold
  [15:8] BIT_BE_FAST_EDCA_TO — be queue fast edca timeout value
  [7] BIT_BE_THRESHOLD_SEL — 1: use all be queue pktnum compare to pktnum_threshold; 0: use single macid pktnum compare to pktnum_threshold;
  [6:0] BIT_BE_FAST_EDCA_PKT_TH — be queue fast edca pkt number threshold
{0x1450+4i} REG_MACID_DROP{i} (i=0..3)
  [31:0] BIT_MACID{32i+31}_{32i}_DROP — Macid{32i+31}~Macid{32i} Drop (per bit controlled)
{0x1460+4i} REG_r_macid_release_success_{i} (i=0..3)
  [31:0] BIT_r_macid_release_success_{i} — macid{32i}~{32i+31}
0x1470 REG_MGQ_FIFO_CTRL access per field reset 0x10000000
  [31] BIT_MGQ_FIFO_EN rw — 1: Enable MGQ FIFO Function. 0: Disable MGQ FIFO Function.
  [30:28] BIT_MGQ_FIFO_PG_SIZE rw — The page size of MGQ FIFO PKTs.
  [27:16] BIT_MGQ_FIFO_START_PG rw — The start page of MGQ FIFO.
  [15:14] BIT_MGQ_FIFO_SIZE rw — 2'b00 : FIFO size 4 pkts. 2'b01 : FIFO size 8 pkts. 2'b1x : FIFO size 16 pkts.
  [13] BIT_MGQ_FIFO_PAUSE rw — 1: use all vo queue pktnum compare to pktnum_threshold; 0: use signle macid pktnum compare to pktnum_threshold;
  [12:8] BIT_MGQ_FIFO_RPTR wo — The read pointer of the MGQ FIFO.(clear when disable MGQ FIFO function)
  [7] BIT_MGQ_FIFO_OV wo — 1: MGQ FIFO overflow. 0: NO MGQ FIFO overflow.
  [6] BIT_MGQ_FIFO_WPTR_ERR wo — 1: Error of MGQ FIFO write pointer setting. 0: No error of MGQ FIFO write pointer setting. (clear when disable MGQ FIFO function)
  [5] BIT_CPUM_LIFETIME_EN rw — 1: Enable Lifetime function of the MGQ FIFO pkts. 0: Disable Lifetime function of the MGQ FIFO pkts.
  [4:0] BIT_MGQ_FIFO_WPTR rw — The write pointer of the MGQ FIFO
0x1474 REG_MGQ_FIFO_RELEASE_INT access per field
  [31:16] BIT_MGQ_FIFO_INT_FLAG wo — The flag of the MGQ FIFO PKT release interrupt, write one clear.
  [15:0] BIT_MGQ_FIFO_INT_MASK rw — The mask of the MGQ FIFO PKT release interrupt.
0x1478 REG_MGQ_FIFO_LIFETIME_VALID access per field reset 0x10000000
  [31:16] BIT_MGQ_FIFO_LIFETIME rw — MGQ FIFO packet lifetime unit: 256us
  [15:8] BIT_MGQ_FIFO_VALID_CLR_1 ro — Clear the valid map of the MGQ FIFO PKT, high [15:8] bits
  [7:0] BIT_MGQ_FIFO_VALID_CLR_0 ro — Clear the valid map of the MGQ FIFO PKT, low [7:0] bits
0x147C REG_r_macid_release_success_clear_offset
  [6:0] BIT_r_macid_release_success_clear_offset — HW will set 0x2460~0x246C if one packet was released successfully for a given macid. SW use this register to reset the status.
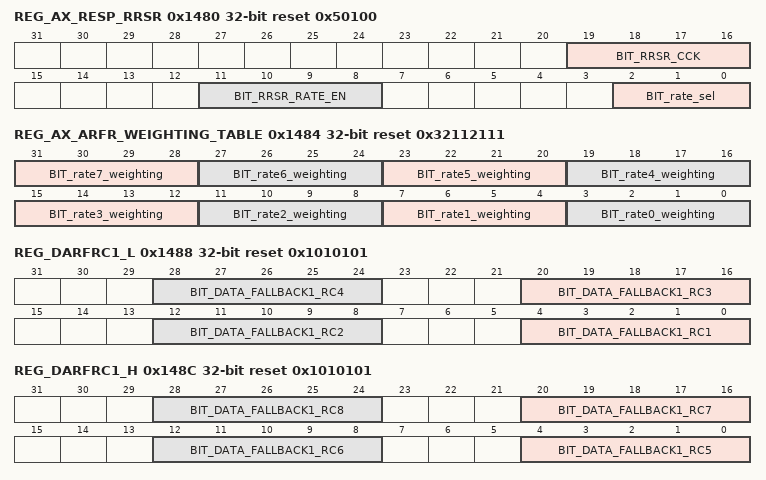
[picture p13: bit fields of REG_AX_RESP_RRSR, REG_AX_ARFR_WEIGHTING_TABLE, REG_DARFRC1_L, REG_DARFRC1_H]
0x1480 REG_AX_RESP_RRSR reset 0x50100
  [19:16] BIT_RRSR_CCK — Response rate BIT[3:0] = {(msb) CCK11, ..., CCK1}
  [11:8] BIT_RRSR_RATE_EN — Enabled response rate mode BIT[2:0] = {(msb) HE rate, VHT rate, HT rate, CCK_OFDM rate}
  [2:0] BIT_rate_sel — New ARFR (REG 0x1484) rate group selection: 0: CCK1M - OFDM18M 1: OFDM24MRSVDOFDM54 , other no use 2: HT MCS0~MCS7 3: HT others, not use 4: VHT1SS/ MCS0~MCS7 5: VHT1SS/ MCS8~MCS9,other no use 6: HE 1SS / MCS0~MCS7 7: HE 1SS / MCS8~MCS9 ,other no use
0x1484 REG_AX_ARFR_WEIGHTING_TABLE reset 0x32112111
  [31:28] BIT_rate7_weighting — Weighting value of the corresponding data rate with respect to rate_sel in reg 0x1480[2:0] 0: disable fallback to the rate 1~15: valid weighting value default is OFDM18M
  [27:24] BIT_rate6_weighting — Weighting value of the corresponding data rate with respect to rate_sel in reg 0x1480[2:0] 0: disable fallback to the rate 1~15: valid weighting value default is OFDM12M
  [23:20] BIT_rate5_weighting — Weighting value of the corresponding data rate with respect to rate_sel in reg 0x1480[2:0] 0: disable fallback to the rate 1~15: valid weighting value default is OFDM9M
  [19:16] BIT_rate4_weighting — Weighting value of the corresponding data rate with respect to rate_sel in reg 0x1480[2:0] 0: disable fallback to the rate 1~15: valid weighting value default is OFDM6M
  [15:12] BIT_rate3_weighting — Weighting value of the corresponding data rate with respect to rate_sel in reg 0x1480[2:0] 0: disable fallback to the rate 1~15: valid weighting value default is CCK11M
  [11:8] BIT_rate2_weighting — Weighting value of the corresponding data rate with respect to rate_sel in reg 0x1480[2:0] 0: disable fallback to the rate 1~15: valid weighting value default is CCK5_5M
  [7:4] BIT_rate1_weighting — Weighting value of the corresponding data rate with respect to rate_sel in reg 0x1480[2:0] 0: disable fallback to the rate 1~15: valid weighting value default is CCK2M
  [3:0] BIT_rate0_weighting — Weighting value of the corresponding data rate with respect to rate_sel in reg 0x1480[2:0] 0: disable fallback to the rate 1~15: valid weighting value default is CCK1M
0x1488 REG_DARFRC1_L reset 0x1010101
  [8n-4:8n-8] BIT_DATA_FALLBACK1_RC{n} (n=1..4) — Data Auto Rate Fallback Retry Count After the number of retry, HW will fall back the rate to the next enabled MAC in ARFR.
0x148C REG_DARFRC1_H reset 0x1010101
  [8n-36:8n-40] BIT_DATA_FALLBACK1_RC{n} (n=5..8) — Data Auto Rate Fallback Retry Count After the number of retry, HW will fall back the rate to the next enabled MAC in ARFR.
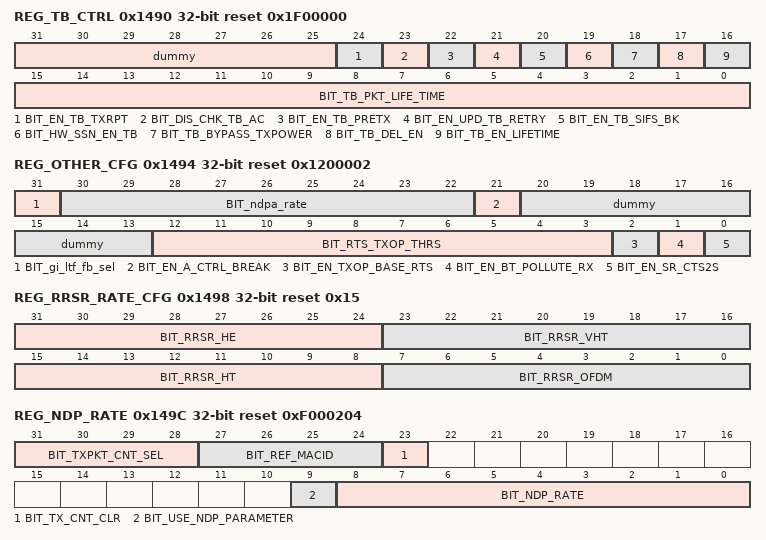
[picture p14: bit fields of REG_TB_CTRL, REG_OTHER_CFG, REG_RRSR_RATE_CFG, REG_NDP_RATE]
0x1490 REG_TB_CTRL reset 0x1F00000
  [31:25] dummy
  [24] BIT_EN_TB_TXRPT — When this bit is set, enable generate report for TB PPDU
  [23] BIT_DIS_CHK_TB_AC — When this bit is set, don't care the AC of DATA
  [22] BIT_EN_TB_PRETX — When this bit is set, enable pretx function of TB PPDU, assert txen before gen_cmd_rdy.
  [21] BIT_EN_UPD_TB_RETRY — enable write retrybit in MH and add retrycnt when TB PPDU TX fail.
  [20] BIT_EN_TB_SIFS_BK — If sifs_timeout_tb_ref (from trxptcl) asserted, break the aggr process of TB PPDU
  [19] BIT_HW_SSN_EN_TB — HW update the SSN [9] for TB PPDU
  [18] BIT_TB_BYPASS_TXPOWER — 1: NOT abort TB PPDU even the txpwr_abort_tx_idx(from txpwr_ctrl) is illegal 0: enable tx power abort TB
  [17] BIT_TB_DEL_EN — Enable TB PPDU packet delete: 1) pkt_ageout; 2) macid_delete
  [16] BIT_TB_EN_LIFETIME — When this bit is set, enable the lifetime function of TB PPDU.
  [15:0] BIT_TB_PKT_LIFE_TIME — LIFETIME Threshold: Unit = 256us. When TB PPDU is triggered, If BIT_TB_EN_LIFETIME = 1, count down. If BIT_TB_EN_LIFETIME = 0, do nothing.
0x1494 REG_OTHER_CFG reset 0x1200002
  [31] BIT_gi_ltf_fb_sel — 0: no GI_LTF fallback 1: GI_LTF fallback option 1 enabled (downgrade GI_LTF first from init. rate) Others RSVD
  [30:22] BIT_ndpa_rate — NDPA tx rate setting, from CCK 1M to VHT NSS2 MCS9
  [21] BIT_EN_A_CTRL_BREAK — 1: break the AGGR process when the a_ctrl field in TXDESC is different
  [20:13] dummy — RSVD
  [12:3] BIT_RTS_TXOP_THRS — unit:32us, valid when BIT_EN_TXOP_BASE_RTS = 1
  [2] BIT_EN_TXOP_BASE_RTS — enable TXOP duration-based RTS/CTS
  [1] BIT_EN_BT_POLLUTE_RX — enable write BT Polluted field during RX RESP
  [0] BIT_EN_SR_CTS2S — enable send cts2s frame during SR
0x1498 REG_RRSR_RATE_CFG reset 0x15
  [31:24] BIT_RRSR_HE — Response rate BIT[35:28]={(msb) HE MCS7, MCS6, ..., MCS0}
  [23:16] BIT_RRSR_VHT — Response rate BIT[27:20] = { (msb) VHT MCS7, MCS6, ..., MCS0}
  [15:8] BIT_RRSR_HT — Response rate BIT[19:12]={(msb) HT MCS7, MCS6, ..., MCS0}
  [7:0] BIT_RRSR_OFDM — Response rate BIT[11:4] = { (msb) OFDM54, OFDM48, ...,OFDM6}
0x149C REG_NDP_RATE reset 0xF000204
  [31:28] BIT_TXPKT_CNT_SEL — Select the counter to show in 0X14A0 BIT_TXPKT_CNT_RPT. 0: r_TX_OK_RTY0 1: r_TX_OK_RTY1 2: r_TX_OK_RTY2 3: r_TX_OK_RTY3 4: r_TX_OK_RTY4 5: r_RTY_DROP 6: r_LT_DROP 7: r_BMC_TXOK 8: r_TOTAL_PKT_CNT 9: r_RTS_DROP 10: r_RTS_OK
  [27:24] BIT_REF_MACID — if BIT_REF_MACID = 0xF, count all eligible frames and ignore MACID; else, only count the frames whose MACID = BIT_REF_MACID BMC packet ignore MACID.
  [23] BIT_TX_CNT_CLR — Write 1 to clear the counters.
  [9] BIT_USE_NDP_PARAMETER — 1: select NDP rate from CR 0X149C[8:0]
  [8:0] BIT_NDP_RATE — NDPA tx rate setting, from CCK 1M to VHT NSS2 MCS9
0x14A0 REG_TXPKT_CNT ro
  [31:0] BIT_TXPKT_CNT_RPT — The results of TXPKT counter. Depends on BIT_TXPKT_CNT_SEL.
